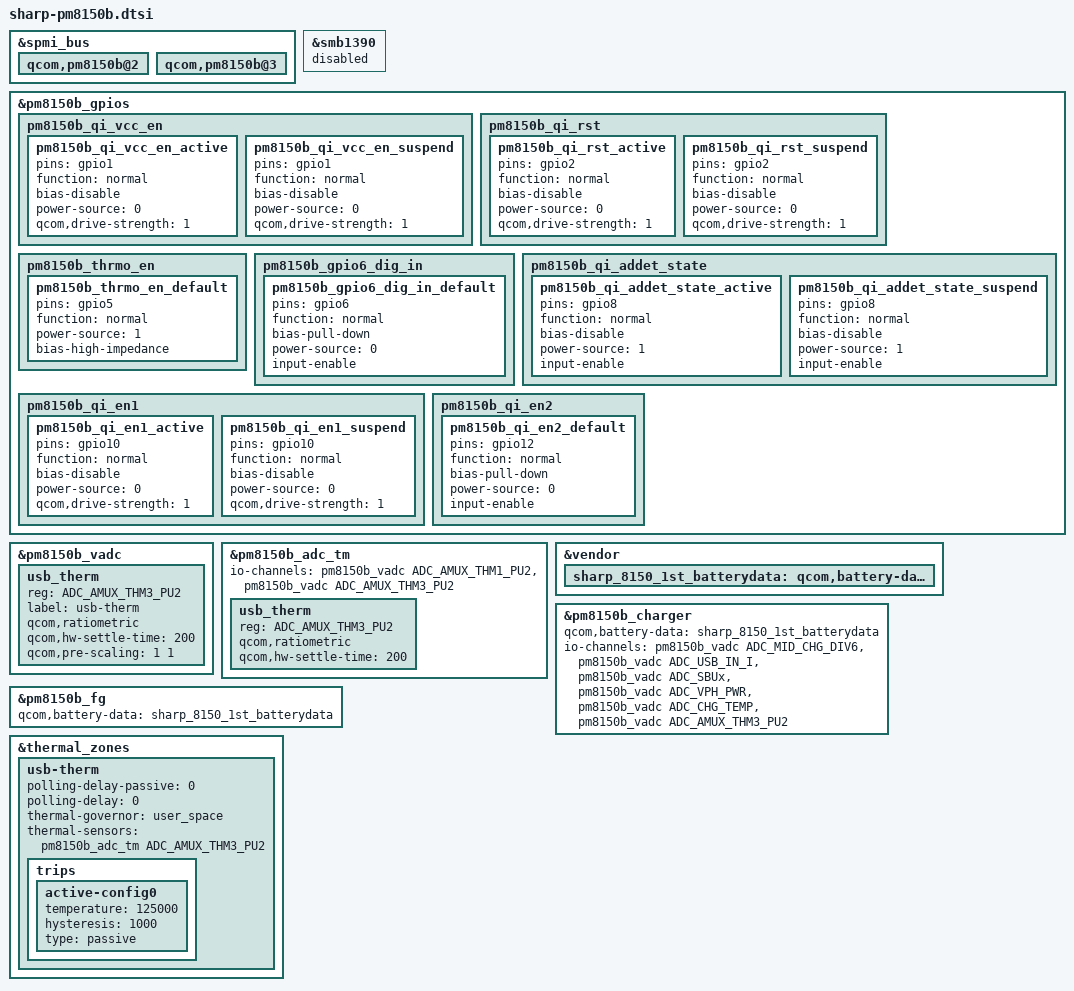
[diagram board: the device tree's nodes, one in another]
/*
 * Copyright (c) 2017-2018, The Linux Foundation. All rights reserved.
 *
 * This program is free software; you can redistribute it and/or modify
 * it under the terms of the GNU General Public License version 2 and
 * only version 2 as published by the Free Software Foundation.
 *
 * This program is distributed in the hope that it will be useful,
 * but WITHOUT ANY WARRANTY; without even the implied warranty of
 * MERCHANTABILITY or FITNESS FOR A PARTICULAR PURPOSE.  See the
 * GNU General Public License for more details.
 */
/*****************************************/
/*  Add SHARP include                    */
/*****************************************/
#include "sharp-chg-param-pm8150b.dtsi"

/*****************************************/
/*  pm8150b: qcom,pm8150b alias            */
/*****************************************/
&spmi_bus {
	qcom,pm8150b@2 {
	};

	qcom,pm8150b@3 {
	};
};

/*****************************************/
/*  pm8150b-gpios: qpnp-pin               */
/*****************************************/
&smb1390{
	status = "disabled";
};

&pm8150b_gpios {
	pm8150b_qi_vcc_en{
		/* O/NP/1 */	/* QI_VCC_EN active */
		pm8150b_qi_vcc_en_active: pm8150b_qi_vcc_en_active{
			pins = "gpio1";			/* GPIO 1 */
			function = "normal";		/* Normal Input */
			bias-disable;			/* No Pull */
			power-source = <0>;		/* VIN0 */
			qcom,drive-strength = <1>;	/* Low strength */
		};

		/* O/NP/1 */	/* QI_VCC_EN suspend */
		pm8150b_qi_vcc_en_suspend: pm8150b_qi_vcc_en_suspend{
			pins = "gpio1";			/* GPIO 1 */
			function = "normal";		/* Normal Input */
			bias-disable;			/* No Pull */
			power-source = <0>;		/* VIN0 */
			qcom,drive-strength = <1>;	/* Low strength */
		};
	};

	pm8150b_qi_rst{
		/* O/NP/1 */	/* QI_RST active */
		pm8150b_qi_rst_active: pm8150b_qi_rst_active{
			pins = "gpio2";			/* GPIO 2 */
			function = "normal";		/* Normal Output */
			bias-disable;			/* No Pull */
			power-source = <0>;		/* VIN0 */
			qcom,drive-strength = <1>;	/* Low strength */
		};

		/* O/NP/0 */	/* QI_RST suspend */
		pm8150b_qi_rst_suspend: pm8150b_qi_rst_suspend{
			pins = "gpio2";			/* GPIO 2 */
			function = "normal";		/* Normal Output */
			bias-disable;			/* No Pull */
			power-source = <0>;		/* VIN0 */
			qcom,drive-strength = <1>;	/* Low strength */
		};
	};

	pm8150b_thrmo_en{
		/* I/NP/Z(H) */	/* - */
		pm8150b_thrmo_en_default: pm8150b_thrmo_en_default{
			pins = "gpio5";			/* GPIO 5 */
			function = "normal";		/* Normal Input */
			power-source = <1>;		/* VIN1 */
			bias-high-impedance;		/* High-Z */
		};
	};

	pm8150b_gpio6_dig_in{
		/* I/PD/L */	/* - */
		pm8150b_gpio6_dig_in_default: pm8150b_gpio6_dig_in_default{
			pins = "gpio6";			/* GPIO 6 */
			function = "normal";		/* Normal Input */
			bias-pull-down;			/* Pull Down */
			power-source = <0>;		/* VIN0 */
			input-enable;			/* Digital Input */
		};
	};

	pm8150b_qi_addet_state{
		/* I/NP/L */	/* QI_ADDET_STATE active */
		pm8150b_qi_addet_state_active: pm8150b_qi_addet_state_active{
			pins = "gpio8";			/* GPIO 8 */
			function = "normal";		/* Normal Input */
			bias-disable;			/* No Pull */
			power-source = <1>;		/* VIN1 */
			input-enable;			/* Digital Input */
		};

		/* I/NP/L */	/* QI_ADDET_STATE suspend */
		pm8150b_qi_addet_state_suspend: pm8150b_qi_addet_state_suspend{
			pins = "gpio8";			/* GPIO 8 */
			function = "normal";		/* Normal Input */
			bias-disable;			/* No Pull */
			power-source = <1>;		/* VIN1 */
			input-enable;			/* Digital Input */
		};
	};

	pm8150b_qi_en1{
		/* O/NP/0 */	/* QI_EN1 active */
		pm8150b_qi_en1_active: pm8150b_qi_en1_active{
			pins = "gpio10";		/* GPIO 10 */
			function = "normal";		/* Normal Output */
			bias-disable;			/* No Pull */
			power-source = <0>;		/* VIN0 */
			qcom,drive-strength = <1>;	/* Low strength */
		};

		/* O/NP/0 */	/* QI_EN1 suspend */
		pm8150b_qi_en1_suspend: pm8150b_qi_en1_suspend{
			pins = "gpio10";		/* GPIO 10 */
			function = "normal";		/* Normal Output */
			bias-disable;			/* No Pull */
			power-source = <0>;		/* VIN0 */
			qcom,drive-strength = <1>;	/* Low strength */
		};
	};

	pm8150b_qi_en2{
		/* I/PD/L */	/* - */
		pm8150b_qi_en2_default: pm8150b_qi_en2_default{
			pins = "gpio12";		/* GPIO 12 */
			function = "normal";		/* Normal Input */
			bias-pull-down;			/* Pull Down */
			power-source = <0>;		/* VIN0 */
			input-enable;			/* Digital Input */
		};
	};

	/delete-node/ smb_stat_default;
};

/*****************************************/
/*  pm8150b_vadc:spmi-adc5               */
/*****************************************/
&pm8150b_vadc {
	usb_therm {
		reg = <ADC_AMUX_THM3_PU2>;
		label = "usb-therm";
		qcom,ratiometric;
		qcom,hw-settle-time = <200>;
		qcom,pre-scaling = <1 1>;
	};
};

/*****************************************/
/*  pm8150b_adc_tm:adc-tm5               */
/*****************************************/
&pm8150b_adc_tm {
	io-channels = <&pm8150b_vadc ADC_AMUX_THM1_PU2>,
			<&pm8150b_vadc ADC_AMUX_THM3_PU2>;

	usb_therm {
		reg = <ADC_AMUX_THM3_PU2>;
		qcom,ratiometric;
		qcom,hw-settle-time = <200>;
	};
};

/*****************************************/
/*  pm8150b_charger:qpnp-smb5            */
/*****************************************/
&vendor {
	sharp_8150_1st_batterydata: qcom,battery-data {
		#include "fg-gen4-batterydata-sharp-8150-1st.dtsi"
	};
};

&pm8150b_charger {
	qcom,battery-data = <&sharp_8150_1st_batterydata>;

	io-channels = <&pm8150b_vadc ADC_MID_CHG_DIV6>,
					<&pm8150b_vadc ADC_USB_IN_I>,
					<&pm8150b_vadc ADC_SBUx>,
					<&pm8150b_vadc ADC_VPH_PWR>,
					<&pm8150b_vadc ADC_CHG_TEMP>,
					<&pm8150b_vadc ADC_AMUX_THM3_PU2>;
	io-channel-names = "mid_voltage",
					"usb_in_current",
					"sbux_res",
					"vph_voltage",
					"chg_temp",
					"usb_therm";
};

/*****************************************/
/*  pm8150b_fg                           */
/*****************************************/
&pm8150b_fg {
	qcom,battery-data = <&sharp_8150_1st_batterydata>;
};

/*****************************************/
/*  thermal_zones                        */
/*****************************************/
&thermal_zones {
	usb-therm {
		polling-delay-passive = <0>;
		polling-delay = <0>;
		thermal-governor = "user_space";
		thermal-sensors = <&pm8150b_adc_tm ADC_AMUX_THM3_PU2>;
		trips {
			active-config0 {
				temperature = <125000>;
				hysteresis = <1000>;
				type = "passive";
			};
		};
	};
};

